# ATSAMD20E15 register map
Vendor: Atmel Corporation; Series: SAMD20; File version: D
CPU: CM0+ r0p1, little endian, no MPU, no FPU, VTOR, 2 interrupt priority bits
Registers are 8-bit, read-write, reset 0x0 unless marked. A register's access mark holds for its fields unless they carry their own. Offsets are from the block's base; [hi:lo] are bit positions; {n}, {i} and the like mark numbered series; 'fields as' and 'values as' point back to an identical list.

## NVMCTRL — Non-Volatile Memory Controller
Base 0x41004000
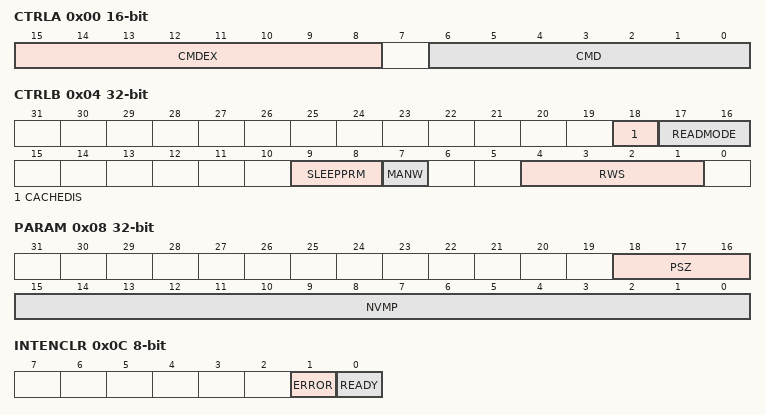
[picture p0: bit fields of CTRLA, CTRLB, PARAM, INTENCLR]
0x00 CTRLA 16-bit — Control A
  [15:8] CMDEX — Command Execution
    165=KEY (Execution Key)
  [6:0] CMD — Command
    2=ER (Erase Row - Erases the row addressed by the ADDR register.); 4=WP (Write Page - Writes the contents of the page buffer to the page addressed by the ADDR register.); 5=EAR (Erase Auxiliary Row - Erases the auxiliary row addressed by the ADDR register. This command can be given only when the security bit is not set and only to the user configuration row.); 6=WAP (Write Auxiliary Page - Writes the contents of the page buffer to the page addressed by the ADDR register. This command can be given only when the security bit is not set and only to the user configuration row.); 10=SF (Security Flow Command); 15=WL (Write lockbits); 64=LR (Lock Region - Locks the region containing the address location in the ADDR register.); 65=UR (Unlock Region - Unlocks the region containing the address location in the ADDR register.); 66=SPRM (Sets the power reduction mode.); 67=CPRM (Clears the power reduction mode.); 68=PBC (Page Buffer Clear - Clears the page buffer.); 69=SSB (Set Security Bit - Sets the security bit by writing 0x00 to the first byte in the lockbit row.); 70=INVALL (Invalidate all cache lines.)
0x04 CTRLB 32-bit — Control B
  [18] CACHEDIS — Cache Disable
  [17:16] READMODE — NVMCTRL Read Mode
    0=NO_MISS_PENALTY (The NVM Controller (cache system) does not insert wait states on a cache miss. Gives the best system performance.); 1=LOW_POWER (Reduces power consumption of the cache system, but inserts a wait state each time there is a cache miss. This mode may not be relevant if CPU performance is required, as the application will be stalled and may lead to increase run time.); 2=DETERMINISTIC (The cache system ensures that a cache hit or miss takes the same amount of time, determined by the number of programmed flash wait states. This mode can be used for real-time applications that require deterministic execution timings.)
  [9:8] SLEEPPRM — Power Reduction Mode during Sleep
    0=WAKEONACCESS (NVM block enters low-power mode when entering sleep.NVM block exits low-power mode upon first access.); 1=WAKEUPINSTANT (NVM block enters low-power mode when entering sleep.NVM block exits low-power mode when exiting sleep.); 3=DISABLED (Auto power reduction disabled.)
  [7] MANW — Manual Write
  [4:1] RWS — NVM Read Wait States
    0=SINGLE (Single Auto Wait State); 1=HALF (Half Auto Wait State); 2=DUAL (Dual Auto Wait State)
0x08 PARAM 32-bit — NVM Parameter
  [18:16] PSZ ro — Page Size
    0=8 bytes; 1=16 bytes; 2=32 bytes; 3=64 bytes; 4=128 bytes; 5=256 bytes; 6=512 bytes; 7=1024 bytes
  [15:0] NVMP ro — NVM Pages
0x0C INTENCLR — Interrupt Enable Clear
  [1] ERROR — Error Interrupt Enable
  [0] READY — NVM Ready Interrupt Enable
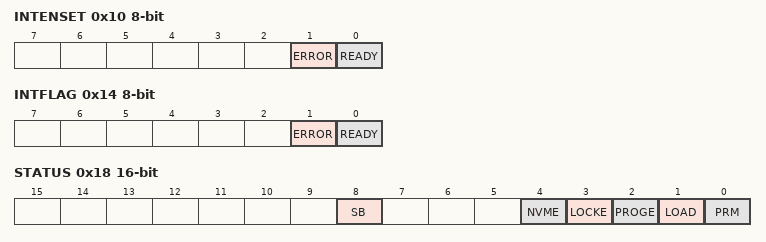
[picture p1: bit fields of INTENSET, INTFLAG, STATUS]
0x10 INTENSET — Interrupt Enable Set
  fields as INTENCLR
0x14 INTFLAG — Interrupt Flag Status and Clear
  [1] ERROR
  [0] READY — NVM Ready
0x18 STATUS 16-bit
  [8] SB ro — Security Bit Status
  [4] NVME — NVM Error
  [3] LOCKE — Lock Error Status
  [2] PROGE — Programming Error Status
  [1] LOAD — NVM Page Buffer Active Loading
  [0] PRM ro — Power Reduction Mode
0x1C ADDR 32-bit — Address
  [21:0] ADDR — NVM Address
0x20 LOCK 16-bit — Lock Section
  [15:0] LOCK ro — Region Lock Bits

## PAC0 — Peripheral Access Controller 0
Base 0x40000000
Same registers: PAC1 0x41000000, PAC2 0x42000000
0x00 WPCLR 32-bit — Write Protection Clear
  [31:1] WP
0x04 WPSET 32-bit — Write Protection Set
  [31:1] WP

## PM — Power Manager
Base 0x40000400
0x00 CTRL — Control
0x01 SLEEP — Sleep Mode
  [1:0] IDLE — Idle Mode Configuration
    0=CPU (The CPU clock domain is stopped); 1=AHB (The CPU and AHB clock domains are stopped); 2=APB (The CPU, AHB and APB clock domains are stopped)
0x08 CPUSEL — CPU Clock Select
  [2:0] CPUDIV — CPU Prescaler Selection
    0=DIV1 (Divide by 1); 1=DIV2 (Divide by 2); 2=DIV4 (Divide by 4); 3=DIV8 (Divide by 8); 4=DIV16 (Divide by 16); 5=DIV32 (Divide by 32); 6=DIV64 (Divide by 64); 7=DIV128 (Divide by 128)
0x09 APBASEL — APBA Clock Select
  [2:0] APBADIV — APBA Prescaler Selection
    values as CPUSEL.CPUDIV
0x0A APBBSEL — APBB Clock Select
  [2:0] APBBDIV — APBB Prescaler Selection
    values as CPUSEL.CPUDIV
0x0B APBCSEL — APBC Clock Select
  [2:0] APBCDIV — APBC Prescaler Selection
    values as CPUSEL.CPUDIV
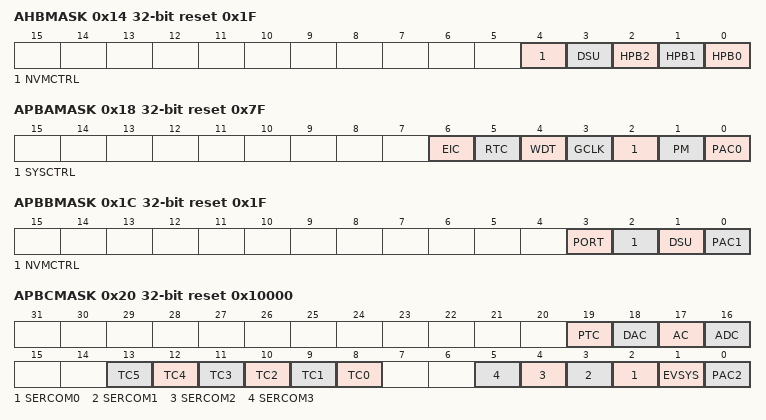
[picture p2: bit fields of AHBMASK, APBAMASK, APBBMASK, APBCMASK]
0x14 AHBMASK 32-bit reset 0x1F
  [4] NVMCTRL — NVMCTRL AHB Clock Mask
  [3] DSU — DSU AHB Clock Mask
  [2] HPB2 — HPB2 AHB Clock Mask
  [1] HPB1 — HPB1 AHB Clock Mask
  [0] HPB0 — HPB0 AHB Clock Mask
0x18 APBAMASK 32-bit reset 0x7F
  [6] EIC — EIC APB Clock Enable
  [5] RTC — RTC APB Clock Enable
  [4] WDT — WDT APB Clock Enable
  [3] GCLK — GCLK APB Clock Enable
  [2] SYSCTRL — SYSCTRL APB Clock Enable
  [1] PM — PM APB Clock Enable
  [0] PAC0 — PAC0 APB Clock Enable
0x1C APBBMASK 32-bit reset 0x1F
  [3] PORT — PORT APB Clock Enable
  [2] NVMCTRL — NVMCTRL APB Clock Enable
  [1] DSU — DSU APB Clock Enable
  [0] PAC1 — PAC1 APB Clock Enable
0x20 APBCMASK 32-bit reset 0x10000
  [19] PTC — PTC APB Clock Enable
  [18] DAC — DAC APB Clock Enable
  [17] AC — AC APB Clock Enable
  [16] ADC — ADC APB Clock Enable
  [n+8] TC{n} (n=0..5) — TC{n} APB Clock Enable
  [n+2] SERCOM{n} (n=0..3) — SERCOM{n} APB Clock Enable
  [1] EVSYS — EVSYS APB Clock Enable
  [0] PAC2 — PAC2 APB Clock Enable
0x34 INTENCLR — Interrupt Enable Clear
  [0] CKRDY — Clock Ready Interrupt Enable
0x35 INTENSET — Interrupt Enable Set
  [0] CKRDY — Clock Ready Interrupt Enable
0x36 INTFLAG — Interrupt Flag Status and Clear
  [0] CKRDY — Clock Ready
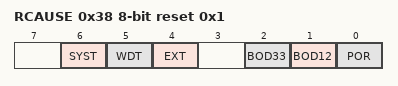
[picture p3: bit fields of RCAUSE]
0x38 RCAUSE ro reset 0x1 — Reset Cause
  [6] SYST — System Reset Request
  [5] WDT — Watchdog Reset
  [4] EXT — External Reset
  [2] BOD33 — Brown Out 33 Detector Reset
  [1] BOD12 — Brown Out 12 Detector Reset
  [0] POR — Power On Reset

## Notices in the file
Atmel Microcontroller Software Support
Copyright (c) 2015, Atmel Corporation
All rights reserved.
Redistribution and use in source and binary forms, with or without
modification, are permitted provided that the following condition is met:
- Redistributions of source code must retain the above copyright notice,
this list of conditions and the disclaimer below.
Atmel's name may not be used to endorse or promote products derived from
this software without specific prior written permission.
DISCLAIMER: THIS SOFTWARE IS PROVIDED BY ATMEL "AS IS" AND ANY EXPRESS OR
IMPLIED WARRANTIES, INCLUDING, BUT NOT LIMITED TO, THE IMPLIED WARRANTIES OF
MERCHANTABILITY, FITNESS FOR A PARTICULAR PURPOSE AND NON-INFRINGEMENT ARE
DISCLAIMED. IN NO EVENT SHALL ATMEL BE LIABLE FOR ANY DIRECT, INDIRECT,
INCIDENTAL, SPECIAL, EXEMPLARY, OR CONSEQUENTIAL DAMAGES (INCLUDING, BUT NOT
LIMITED TO, PROCUREMENT OF SUBSTITUTE GOODS OR SERVICES; LOSS OF USE, DATA,
OR PROFITS; OR BUSINESS INTERRUPTION) HOWEVER CAUSED AND ON ANY THEORY OF
LIABILITY, WHETHER IN CONTRACT, STRICT LIABILITY, OR TORT (INCLUDING
NEGLIGENCE OR OTHERWISE) ARISING IN ANY WAY OUT OF THE USE OF THIS SOFTWARE,
EVEN IF ADVISED OF THE POSSIBILITY OF SUCH DAMAGE.
